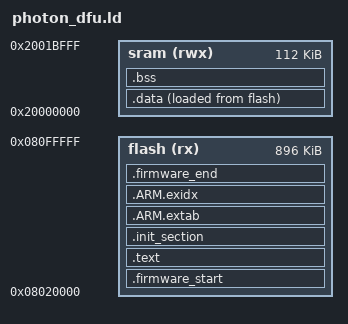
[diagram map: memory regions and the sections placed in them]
/****************************************************************************
 * boards/arm/stm32/photon/scripts/photon_dfu.ld
 *
 *   Copyright (C) 2017 Gregory Nutt. All rights reserved.
 *
 * Redistribution and use in source and binary forms, with or without
 * modification, are permitted provided that the following conditions
 * are met:
 *
 * 1. Redistributions of source code must retain the above copyright
 *    notice, this list of conditions and the following disclaimer.
 * 2. Redistributions in binary form must reproduce the above copyright
 *    notice, this list of conditions and the following disclaimer in
 *    the documentation and/or other materials provided with the
 *    distribution.
 * 3. Neither the name NuttX nor the names of its contributors may be
 *    used to endorse or promote products derived from this software
 *    without specific prior written permission.
 *
 * THIS SOFTWARE IS PROVIDED BY THE COPYRIGHT HOLDERS AND CONTRIBUTORS
 * "AS IS" AND ANY EXPRESS OR IMPLIED WARRANTIES, INCLUDING, BUT NOT
 * LIMITED TO, THE IMPLIED WARRANTIES OF MERCHANTABILITY AND FITNESS
 * FOR A PARTICULAR PURPOSE ARE DISCLAIMED. IN NO EVENT SHALL THE
 * COPYRIGHT OWNER OR CONTRIBUTORS BE LIABLE FOR ANY DIRECT, INDIRECT,
 * INCIDENTAL, SPECIAL, EXEMPLARY, OR CONSEQUENTIAL DAMAGES (INCLUDING,
 * BUT NOT LIMITED TO, PROCUREMENT OF SUBSTITUTE GOODS OR SERVICES; LOSS
 * OF USE, DATA, OR PROFITS; OR BUSINESS INTERRUPTION) HOWEVER CAUSED
 * AND ON ANY THEORY OF LIABILITY, WHETHER IN CONTRACT, STRICT
 * LIABILITY, OR TORT (INCLUDING NEGLIGENCE OR OTHERWISE) ARISING IN
 * ANY WAY OUT OF THE USE OF THIS SOFTWARE, EVEN IF ADVISED OF THE
 * POSSIBILITY OF SUCH DAMAGE.
 *
 ****************************************************************************/

/* The STM32F205RG has 1024Kb of FLASH beginning at address 0x0800:0000 and
 * 112Kb of SRAM in main SRAM1 and 16 Kb in auxiliary SRAM2.
 *
 * Bootloader jumps at 0x0802:0000.
 */

MEMORY
{
  flash (rx) : ORIGIN = 0x08020000, LENGTH = 896K
  sram (rwx) : ORIGIN = 0x20000000, LENGTH = 112K
}

OUTPUT_ARCH(arm)
ENTRY(_stext)
EXTERN(dfu_sign)

SECTIONS
{
    .firmware_start : {
        _firmware_start = ABSOLUTE(.);
    } > flash

    .text : {
        _stext = ABSOLUTE(.);
        *(.vectors)
        *(.dfu_signature)
        *(.text .text.*)
        *(.fixup)
        *(.gnu.warning)

        . = ALIGN(0x4);
        wlan_firmware_image_location = .;
        *(.wlan_firmware_image .wlan_firmware_image.*)
        wlan_firmware_image_end = .;
        . = ALIGN(0x4);
        wlan_nvram_image_location = .;
        *(.wlan_nvram_image .wlan_nvram_image.*)
        wlan_nvram_image_end = .;

        *(.rodata .rodata.*)
        *(.gnu.linkonce.t.*)
        *(.glue_7)
        *(.glue_7t)
        *(.got)
        *(.gcc_except_table)
        *(.gnu.linkonce.r.*)
        _etext = ABSOLUTE(.);
    } > flash

    .init_section : {
        _sinit = ABSOLUTE(.);
        *(.init_array .init_array.*)
        _einit = ABSOLUTE(.);
    } > flash

    .ARM.extab : {
        *(.ARM.extab*)
    } > flash

    __exidx_start = ABSOLUTE(.);
    .ARM.exidx : {
        *(.ARM.exidx*)
    } > flash
    __exidx_end = ABSOLUTE(.);

    _eronly = ABSOLUTE(.);

    .data : {
        _sdata = ABSOLUTE(.);
        *(.data .data.*)
        *(.gnu.linkonce.d.*)
        CONSTRUCTORS
        . = ALIGN(4);
        _edata = ABSOLUTE(.);
    } > sram AT > flash

    .firmware_end : {
        _firmware_end = ABSOLUTE(.);
    } > flash

    .bss : {
        _sbss = ABSOLUTE(.);
        *(.bss .bss.*)
        *(.gnu.linkonce.b.*)
        *(COMMON)
        . = ALIGN(4);
        _ebss = ABSOLUTE(.);
    } > sram

    /* Stabs debugging sections. */
    .stab 0 : { *(.stab) }
    .stabstr 0 : { *(.stabstr) }
    .stab.excl 0 : { *(.stab.excl) }
    .stab.exclstr 0 : { *(.stab.exclstr) }
    .stab.index 0 : { *(.stab.index) }
    .stab.indexstr 0 : { *(.stab.indexstr) }
    .comment 0 : { *(.comment) }
    .debug_abbrev 0 : { *(.debug_abbrev) }
    .debug_info 0 : { *(.debug_info) }
    .debug_line 0 : { *(.debug_line) }
    .debug_pubnames 0 : { *(.debug_pubnames) }
    .debug_aranges 0 : { *(.debug_aranges) }
}
